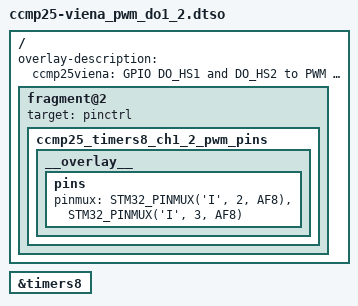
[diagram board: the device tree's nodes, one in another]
/dts-v1/;
/plugin/;

#include <dt-bindings/pinctrl/stm32-pinfunc.h>

/ {

    fragment@0 {
        target-path = "/";
        __overlay__ {
            overlay-description = "ccmp25viena: GPIO DO_HS1 and DO_HS2 to PWM Overlay (TIM8_CH1 and TIM8_CH2 on PI2,PI3)";
        };
    };

    fragment@1 {
        target = <&timers8>;
        __overlay__ {
            status = "okay"; 
        };
    };

    fragment@2 {
        target = <&pinctrl>;
        ccmp25_timers8_ch1_2_pwm_pins {
            __overlay__ {
                pins {
                    /* convert to pwm ：GPIO -> AF8 */
                    pinmux = <STM32_PINMUX('I', 2, AF8)>,  /* TIM8_CH1 */
                             <STM32_PINMUX('I', 3, AF8)>; /* TIM8_CH2 */                 
                };
            };
        };
    };
};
